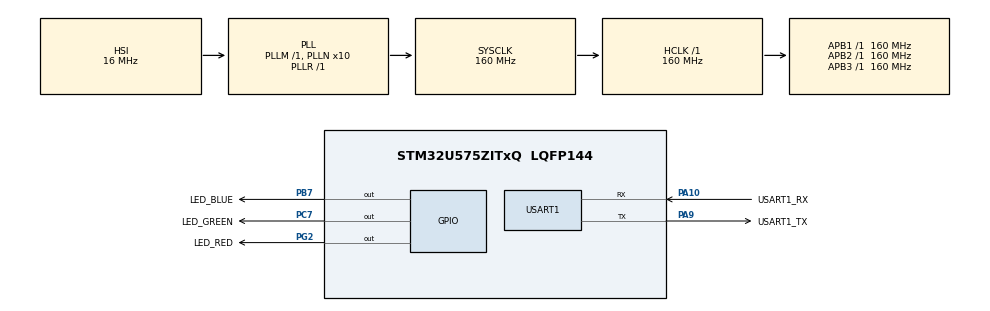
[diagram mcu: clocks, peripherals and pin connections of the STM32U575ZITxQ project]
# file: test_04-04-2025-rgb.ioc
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CORTEX_M33_NS.userName=CORTEX_M33
Mcu.Family=STM32U5
Mcu.Name=STM32U575ZITxQ
Mcu.Package=LQFP144
NVIC.PriorityGroup=NVIC_PRIORITYGROUP_4
PA10.GPIO_Label=USART1_RX
PA10.GPIO_Speed=GPIO_SPEED_FREQ_HIGH
PA10.Mode=Asynchronous
PA10.Signal=USART1_RX
PA9.GPIO_Label=USART1_TX
PA9.GPIO_ModeDefaultPP=GPIO_MODE_AF_PP
PA9.GPIO_Speed=GPIO_SPEED_FREQ_HIGH
PA9.Mode=Asynchronous
PA9.Signal=USART1_TX
PB7.GPIO_Label=LED_BLUE
PB7.PinState=GPIO_PIN_SET
PB7.Signal=GPIO_Output
PC7.GPIO_Label=LED_GREEN
PC7.PinState=GPIO_PIN_SET
PC7.Signal=GPIO_Output
PG2.GPIO_Label=LED_RED
PG2.PinState=GPIO_PIN_SET
PG2.Signal=GPIO_Output
ProjectManager.HeapSize=0x200
ProjectManager.StackSize=0x400
ProjectManager.TargetToolchain=CMake
RCC.ADCFreq_Value=16000000
RCC.AHBFreq_Value=160000000
RCC.APB1Freq_Value=160000000
RCC.APB1TimFreq_Value=160000000
RCC.APB2Freq_Value=160000000
RCC.APB2TimFreq_Value=160000000
RCC.APB3Freq_Value=160000000
RCC.CortexFreq_Value=160000000
RCC.EPOD_VALUE=16000000
RCC.HCLKFreq_Value=160000000
RCC.HSE_VALUE=16000000
RCC.HSI48_VALUE=48000000
RCC.HSI_VALUE=16000000
RCC.LSE_VALUE=32768
RCC.LSIDIV_VALUE=32000
RCC.MSIClockRange=RCC_MSIRANGE_0
RCC.MSI_VALUE=48000000
RCC.PLL1R=1
RCC.PLL2FRACN=0
RCC.PLL3FRACN=0
RCC.PLLFRACN=0
RCC.PLLN=10
RCC.PLLSourceVirtual=RCC_PLLSOURCE_HSI
RCC.SYSCLKFreq_VALUE=160000000
RCC.SYSCLKSource=RCC_SYSCLKSOURCE_PLLCLK
RCC.USBFreq_Value=48000000
RCC.VCOOutputFreq_Value=160000000
USART1.VirtualMode-Asynchronous=VM_ASYNC
VP_LPBAMQUEUE_VS_QUEUE.Mode=QUEUEMODE
VP_LPBAM_VS_SIG1.Mode=SmartRun
VP_LPBAM_VS_SIG4.Mode=LPDMA1
VP_MEMORYMAP_VS_MEMORYMAP.Mode=CurAppReg
VP_PWR_VS_SECSignals.Mode=Security/Privilege
board=custom

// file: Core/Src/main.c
/* USER CODE BEGIN Header */
/**
  ******************************************************************************
  * @file           : main.c
  * @brief          : Main program body
  ******************************************************************************
  * @attention
  *
  * Copyright (c) 2025 STMicroelectronics.
  * All rights reserved.
  *
  * This software is licensed under terms that can be found in the LICENSE file
  * in the root directory of this software component.
  * If no LICENSE file comes with this software, it is provided AS-IS.
  *
  ******************************************************************************
  */
/* USER CODE END Header */
#include "main.h"

UART_HandleTypeDef huart1;

void SystemClock_Config(void);
static void MX_GPIO_Init(void);
static void MX_USART1_UART_Init(void);

int main(void)
{

  /* MCU Configuration--------------------------------------------------------*/

  /* Reset of all peripherals, Initializes the Flash interface and the Systick. */
  HAL_Init();

  /* Configure the system clock */
  SystemClock_Config();

  /* Initialize all configured peripherals */
  MX_GPIO_Init();
  MX_USART1_UART_Init();
  /* Infinite loop */
  while (1)
  {

    /* USER CODE BEGIN 3 */
    //HAL_GPIO_TogglePin (GPIOG, GPIO_PIN_2);
    //HAL_Delay (100);   /* Insert delay 100 ms */
    HAL_GPIO_WritePin(LED_RED_GPIO_Port, LED_RED_Pin, GPIO_PIN_SET);
    HAL_Delay(100);
    HAL_GPIO_WritePin(LED_RED_GPIO_Port, LED_RED_Pin, GPIO_PIN_RESET);
    HAL_Delay(100);
    HAL_GPIO_WritePin(LED_BLUE_GPIO_Port, LED_BLUE_Pin, GPIO_PIN_SET);
    HAL_Delay(100);
    HAL_GPIO_WritePin(LED_BLUE_GPIO_Port, LED_BLUE_Pin, GPIO_PIN_RESET);
    HAL_Delay(100);
    HAL_GPIO_WritePin(LED_GREEN_GPIO_Port, LED_GREEN_Pin, GPIO_PIN_SET);
    HAL_Delay(100);
    HAL_GPIO_WritePin(LED_GREEN_GPIO_Port, LED_GREEN_Pin, GPIO_PIN_RESET);

    /* HAL_GPIO_TogglePin(LED_BLUE_GPIO_Port, LED_BLUE_Pin);
    HAL_Delay(100); */
  }
}
  /* USER CODE END 3 */

void SystemClock_Config(void)
{
  RCC_OscInitTypeDef RCC_OscInitStruct = {0};
  RCC_ClkInitTypeDef RCC_ClkInitStruct = {0};

  /** Configure the main internal regulator output voltage
  */
  if (HAL_PWREx_ControlVoltageScaling(PWR_REGULATOR_VOLTAGE_SCALE1) != HAL_OK)
  {
    Error_Handler();
  }

  /** Initializes the CPU, AHB and APB buses clocks
  */
  RCC_OscInitStruct.OscillatorType = RCC_OSCILLATORTYPE_HSI;
  RCC_OscInitStruct.HSIState = RCC_HSI_ON;
  RCC_OscInitStruct.HSICalibrationValue = RCC_HSICALIBRATION_DEFAULT;
  RCC_OscInitStruct.PLL.PLLState = RCC_PLL_ON;
  RCC_OscInitStruct.PLL.PLLSource = RCC_PLLSOURCE_HSI;
  RCC_OscInitStruct.PLL.PLLMBOOST = RCC_PLLMBOOST_DIV1;
  RCC_OscInitStruct.PLL.PLLM = 1;
  RCC_OscInitStruct.PLL.PLLN = 10;
  RCC_OscInitStruct.PLL.PLLP = 2;
  RCC_OscInitStruct.PLL.PLLQ = 2;
  RCC_OscInitStruct.PLL.PLLR = 1;
  RCC_OscInitStruct.PLL.PLLRGE = RCC_PLLVCIRANGE_1;
  RCC_OscInitStruct.PLL.PLLFRACN = 0;
  if (HAL_RCC_OscConfig(&RCC_OscInitStruct) != HAL_OK)
  {
    Error_Handler();
  }

  /** Initializes the CPU, AHB and APB buses clocks
  */
  RCC_ClkInitStruct.ClockType = RCC_CLOCKTYPE_HCLK|RCC_CLOCKTYPE_SYSCLK
                              |RCC_CLOCKTYPE_PCLK1|RCC_CLOCKTYPE_PCLK2
                              |RCC_CLOCKTYPE_PCLK3;
  RCC_ClkInitStruct.SYSCLKSource = RCC_SYSCLKSOURCE_PLLCLK;
  RCC_ClkInitStruct.AHBCLKDivider = RCC_SYSCLK_DIV1;
  RCC_ClkInitStruct.APB1CLKDivider = RCC_HCLK_DIV1;
  RCC_ClkInitStruct.APB2CLKDivider = RCC_HCLK_DIV1;
  RCC_ClkInitStruct.APB3CLKDivider = RCC_HCLK_DIV1;

  if (HAL_RCC_ClockConfig(&RCC_ClkInitStruct, FLASH_LATENCY_4) != HAL_OK)
  {
    Error_Handler();
  }
}

static void MX_USART1_UART_Init(void)
{

  huart1.Instance = USART1;
  huart1.Init.BaudRate = 115200;
  huart1.Init.WordLength = UART_WORDLENGTH_8B;
  huart1.Init.StopBits = UART_STOPBITS_1;
  huart1.Init.Parity = UART_PARITY_NONE;
  huart1.Init.Mode = UART_MODE_TX_RX;
  huart1.Init.HwFlowCtl = UART_HWCONTROL_NONE;
  huart1.Init.OverSampling = UART_OVERSAMPLING_16;
  huart1.Init.OneBitSampling = UART_ONE_BIT_SAMPLE_DISABLE;
  huart1.Init.ClockPrescaler = UART_PRESCALER_DIV1;
  huart1.AdvancedInit.AdvFeatureInit = UART_ADVFEATURE_NO_INIT;
  if (HAL_UART_Init(&huart1) != HAL_OK)
  {
    Error_Handler();
  }
  if (HAL_UARTEx_SetTxFifoThreshold(&huart1, UART_TXFIFO_THRESHOLD_1_8) != HAL_OK)
  {
    Error_Handler();
  }
  if (HAL_UARTEx_SetRxFifoThreshold(&huart1, UART_RXFIFO_THRESHOLD_1_8) != HAL_OK)
  {
    Error_Handler();
  }
  if (HAL_UARTEx_DisableFifoMode(&huart1) != HAL_OK)
  {
    Error_Handler();
  }

}

static void MX_GPIO_Init(void)
{
  GPIO_InitTypeDef GPIO_InitStruct = {0};

  /* GPIO Ports Clock Enable */
  __HAL_RCC_GPIOG_CLK_ENABLE();
  __HAL_RCC_GPIOC_CLK_ENABLE();
  __HAL_RCC_GPIOA_CLK_ENABLE();
  __HAL_RCC_GPIOB_CLK_ENABLE();

  /*Configure GPIO pin Output Level */
  HAL_GPIO_WritePin(LED_RED_GPIO_Port, LED_RED_Pin, GPIO_PIN_SET);

  /*Configure GPIO pin Output Level */
  HAL_GPIO_WritePin(LED_GREEN_GPIO_Port, LED_GREEN_Pin, GPIO_PIN_SET);

  /*Configure GPIO pin Output Level */
  HAL_GPIO_WritePin(LED_BLUE_GPIO_Port, LED_BLUE_Pin, GPIO_PIN_SET);

  /*Configure GPIO pin : LED_RED_Pin */
  GPIO_InitStruct.Pin = LED_RED_Pin;
  GPIO_InitStruct.Mode = GPIO_MODE_OUTPUT_PP;
  GPIO_InitStruct.Pull = GPIO_NOPULL;
  GPIO_InitStruct.Speed = GPIO_SPEED_FREQ_LOW;
  HAL_GPIO_Init(LED_RED_GPIO_Port, &GPIO_InitStruct);

  /*Configure GPIO pin : LED_GREEN_Pin */
  GPIO_InitStruct.Pin = LED_GREEN_Pin;
  GPIO_InitStruct.Mode = GPIO_MODE_OUTPUT_PP;
  GPIO_InitStruct.Pull = GPIO_NOPULL;
  GPIO_InitStruct.Speed = GPIO_SPEED_FREQ_LOW;
  HAL_GPIO_Init(LED_GREEN_GPIO_Port, &GPIO_InitStruct);

  /*Configure GPIO pin : LED_BLUE_Pin */
  GPIO_InitStruct.Pin = LED_BLUE_Pin;
  GPIO_InitStruct.Mode = GPIO_MODE_OUTPUT_PP;
  GPIO_InitStruct.Pull = GPIO_NOPULL;
  GPIO_InitStruct.Speed = GPIO_SPEED_FREQ_LOW;
  HAL_GPIO_Init(LED_BLUE_GPIO_Port, &GPIO_InitStruct);

}

/* USER CODE BEGIN 4 */
/* void HAL_UART_RxCpltCallback(UART_HandleTypeDef *huart) {
	HAL_UART_Receive_IT(&huart1, buffer, 1);
	HAL_UART_Transmit(&huart1, buffer, 1, 0xFFFF);
} */
/* USER CODE END 4 */

void Error_Handler(void)
{
  __disable_irq();
  while (1)
  {
  }
}
